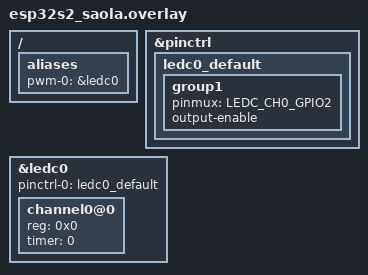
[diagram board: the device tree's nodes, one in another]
/*
 * SPDX-License-Identifier: Apache-2.0
 *
 * Copyright (c) 2023 Espressif Systems (Shanghai) Co., Ltd.
 */

#include <zephyr/dt-bindings/pwm/pwm.h>
#include <dt-bindings/pinctrl/esp32s2-pinctrl.h>

/ {
	aliases {
		pwm-0 = &ledc0;
	};
};

&pinctrl {
	ledc0_default: ledc0_default {
		group1 {
			pinmux = <LEDC_CH0_GPIO2>;
			output-enable;
		};
	};
};

&ledc0 {
	pinctrl-0 = <&ledc0_default>;
	pinctrl-names = "default";
	status = "okay";
	#address-cells = <1>;
	#size-cells = <0>;
	channel0@0 {
		reg = <0x0>;
		timer = <0>;
	};
};
